# STM32G071 register map
File version: 2.5
CPU: CM0 r0p1, little endian, MPU, no FPU, 2 interrupt priority bits
Registers are 32-bit, read-write, reset 0x0 unless marked. A register's access mark holds for its fields unless they carry their own. Offsets are from the block's base; lines under a group give offsets from that group; [hi:lo] are bit positions; {n}, {i} and the like mark numbered series; 'fields as' and 'values as' point back to an identical list; <NAME> marks a mode.

## Memory map
0x40000000 TIM2 size 0x400 — General-purpose-timers
0x40000400 TIM3 size 0x400 — General-purpose-timers
0x40001000 TIM6 size 0x400 — Basic timers
0x40001400 TIM7 size 0x400
0x40002000 TIM14 size 0x400 — General purpose timers
0x40002800 RTC size 0x400 — Real-time clock
0x40002C00 WWDG size 0x400 — System window watchdog
0x40003000 IWDG size 0x400 — Independent watchdog
0x40003800 SPI2 size 0x400
0x40004400 USART2 size 0x400
0x40004800 USART3 size 0x400
0x40004C00 USART4 size 0x400
0x40005400 I2C1 size 0x400 — Inter-integrated circuit
0x40005800 I2C2 size 0x400
0x40007000 PWR size 0x400 — Power control
0x40007400 DAC size 0x400
0x40007800 HDMI_CEC size 0x400
0x40007C00 LPTIM1 size 0x400 — Low power timer
0x40008000 LPUART size 0x400 — Universal synchronous asynchronous receiver transmitter
0x40009400 LPTIM2 size 0x400
0x4000A000 UCPD1 size 0x400 — USB Power Delivery interface
0x4000A400 UCPD2 size 0x400
0x4000B000 TAMP size 0x400 — Tamper and backup registers
0x40010000 SYSCFG size 0x100 — System configuration controller
0x40010030 VREFBUF size 0x400 — System configuration controller
0x40010200 COMP size 0x200 — COMP1
0x40012400 ADC size 0x400 — Analog to Digital Converter instance 1
0x40012C00 TIM1 size 0x400 — Advanced-timers
0x40013000 SPI1 size 0x400 — Serial peripheral interface/Inter-IC sound
0x40013800 USART1 size 0x400 — Universal synchronous asynchronous receiver transmitter
0x40014000 TIM15 size 0x400 — General purpose timers
0x40014400 TIM16 size 0x400 — General purpose timers
0x40014800 TIM17 size 0x400
0x40015800 DBG size 0x400 — Debug support
0x40020000 DMA1 size 0x400 — DMA controller
0x40020800 DMAMUX size 0x400
0x40021000 RCC size 0x400 — Reset and clock control
0x40021800 EXTI size 0x400 — External interrupt/event controller
0x40022000 FLASH size 0x400
0x40023000 CRC size 0x400 — Cyclic redundancy check calculation unit
0x50000000 GPIOA size 0x400 — General-purpose I/Os
0x50000400 GPIOB size 0x400 — General-purpose I/Os
0x50000800 GPIOC size 0x400
0x50000C00 GPIOD size 0x400
0x50001400 GPIOF size 0x400

## Interrupts
0 WWDG — Window watchdog interrupt
1 PVD (PWR) — Power voltage detector interrupt
2 RTC_STAMP (RTC) — RTC and TAMP interrupts
3 FLASH — Flash global interrupt
4 RCC — RCC global interrupt
5 EXTI0_1 (EXTI) — EXTI line 0 & 1 interrupt
6 EXTI2_3 (EXTI) — EXTI line 2 & 3 interrupt
7 EXTI4_15 (EXTI) — EXTI line 4 to 15 interrupt
8 UCPD1_UCPD2 (UCPD1) — UCPD global interrupt
9 DMA1_Channel1 (DMA1) — DMA channel 1 interrupt
10 DMA1_Channel2_3 (DMA1) — DMA channel 2 and 3 interrupts
11 DMA1_Channel4_5_6_7_DMAMUX (DMA1) — interrupts for DMA1 channels 4-7 and DMAMUX
12 ADC_COMP (ADC) — ADC and COMP interrupts
13 TIM1_BRK_UP_TRG_COM (TIM1) — TIM1 break, update, trigger and commutation interrupts
14 TIM1_CC (TIM1) — TIM1 Capture Compare interrupt
15 TIM2 — TIM2 global interrupt
16 TIM3 (TIM2) — TIM3 global interrupt
17 TIM6_DAC_LPTIM1 (TIM6) — TIM6 + LPTIM1 and DAC global interrupt
18 TIM7_LPTIM2 (TIM7) — TIM7 + LPTIM2 global interrupt
19 TIM14 — TIM14 global interrupt
20 TIM15 — Timer 15 global interrupt
21 TIM16 — TIM16 global interrupt
22 TIM17 — TIM17 global interrupt
23 I2C1 — I2C1 global interrupt
24 I2C2 — I2C2 global interrupt
25 SPI1 — SPI1 global interrupt
26 SPI2 — SPI2 global interrupt
27 USART1 — USART1 global interrupt
28 USART2 — USART2 global interrupt
29 USART3_USART4_LPUART1 (USART3)
30 CEC (CRC) — CEC global interrupt

## IWDG — Independent watchdog
Base 0x40003000
0x00 KR 16-bit wo — Key register
  [15:0] KEY — Key value (write only, read 0x0000)
    0x5555=Unlock (Enable access to PR, RLR and WINR registers); 0xAAAA=Feed watchdog with RLR register value; 0xCCCC=Start the watchdog
0x04 PR 16-bit — Prescaler register
  [2:0] PR — Prescaler divider
    0=DivideBy4 (Divider /4); 1=DivideBy8 (Divider /8); 2=DivideBy16 (Divider /16); 3=DivideBy32 (Divider /32); 4=DivideBy64 (Divider /64); 5=DivideBy128 (Divider /128); other=DivideBy256 (Divider /256)
0x08 RLR 16-bit reset 0xFFF — Reload register
  [11:0] RL — Watchdog counter reload value
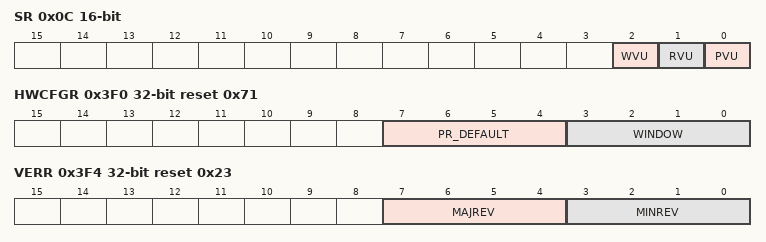
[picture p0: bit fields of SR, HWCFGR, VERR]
0x0C SR 16-bit ro — Status register
  [2] WVU — Watchdog counter window value update
  [1] RVU — Watchdog counter reload value update
  [0] PVU — Watchdog prescaler value update
0x10 WINR 16-bit reset 0xFFF — Window register
  [11:0] WIN — Watchdog counter window value
0x3F0 HWCFGR reset 0x71 — hardware configuration register
  [7:4] PR_DEFAULT — Prescaler default value
  [3:0] WINDOW — Support of Window function
0x3F4 VERR ro reset 0x23 — EXTI IP Version register
  [7:4] MAJREV — Major Revision number
  [3:0] MINREV — Minor Revision number
0x3F8 IPIDR ro reset 0x120041 — EXTI Identification register
  [31:0] IPID — IP Identification
0x3FC SIDR ro reset 0xA3C5DD01 — EXTI Size ID register
  [31:0] SID — Size Identification
